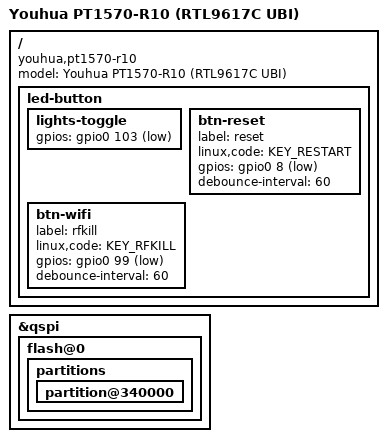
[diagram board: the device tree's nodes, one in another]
// SPDX-License-Identifier: GPL-2.0-only
//
// UNVERIFIED — DO NOT FLASH. 已按真机 FDT 完成静态移植，但尚未在新固件上启动验证。
//
// FDT_VERIFIED (2026-11-09)：以下字段来自 PT1570-R10 真机 /proc/device-tree
// 只读导出（pt1570-ci-research/r10-fdt-dump-20261109.txt，447 个属性），
// 并与 dreamtekcat/PonWRT-TYFZA1@pt1570 的 port/overlay DTS 交叉核对。
//
// 统一 UBI 方案部分完全由上游 rtl9617c-tyfza1.dtsi 提供，本文件不重复：
//   chosen.rootdisk = <&ubi_rootdisk>
//   ubi-volume-fit      { volname = "fit"; }
//   ubi-volume-factory  { volname = "factory"; nvmem-layout { ... }; }
//   分区 ubi_device <0x340000 0xf5c0000> —— 与真机 FDT 实测一致。
//
// ---- 已实证一致（由 include 的上游 4GE 定义提供，无需覆盖） ----
//   * 4×GE：realtek,lan-phys 是 4 个 phandle，指向 mdio 的 phy@1..phy@4
//     （reg 1/2/3/4，内部 GPHY）；真机 dmesg 也报 PHY 001ccac4、lan1..lan4。
//   * 12 个 LED 的 GPIO 与极性逐项一致（L=低有效 / H=高有效）：
//       internet 2L, los 10L, usb0 7H, pon 9L, power 11H, phone 12H,
//       lan0 4L, lan1 3L, lan2 1L, lan3 0L, usb1 6L, wps 5H
//   * flash 分区表 5 个分区与真机 /proc/mtd 一致。
//   * chosen / stdout-path、PON、PCIe0/PCIe1、USB、BOSA 节点由 dtsi 提供。
//
// ---- 已实证不一致、本文件覆盖 ----
//   * 按键：上游 dtsi 只有 lights-toggle(gpio 67)；真机有三键，见下方节点。
//
// ⛔ 不得改用 2.5G 板定义：它会引入一颗外置 2.5G PHY、把网口映射改成
//    NI 端口 0/1/2/4，并换成另一套 LED GPIO。R10 是 4×GE，误用会直接
//    导致 LAN 不通。这是 2026-11-09 真机核对后修正的实质缺陷。
//
// ---- 仍待验证（因此保留 UNVERIFIED） ----
//   1. 本 DTS 编译出的固件尚未在 R10 上启动过；
//   2. U-Boot Web Failsafe 网口在 R10（4×GE）上未实测；
//   3. PON / PCIe0(10ec:c852) / PCIe1(10ec:0192) / LED / 按键需开机后复测；
//   4. bootargs / rootdisk 完全沿用上游 dtsi，不在本文件覆盖。Run14 实测
//      该形态可刷入启动（当时仅 IPv4 网络层不通，已由 95-pt1570-wan-default
//      修复）；run15 起误加 /chosen 覆盖块反而把刷入态启动搞坏，见下方注释。
//
// 完成上述真机启动验证、删除 UNVERIFIED 标记后，才允许以
// dts_status=verified 编译并发布 Release。
//
// 注意：不要在此文件写 /dts-v1/；被 include 的 .dts 已经带了该标记。

#include "rtl9617c-tyfza1-4ge.dts"

/ {
	model = "Youhua PT1570-R10 (RTL9617C UBI)";
	compatible = "youhua,pt1570-r10", "tianyi,tyfza1-4ge", "realtek,rtl9617c";

	/*
	 * ⛔ 不要在这里写 /chosen 覆盖块 —— 这是 run15~run22 刷入态起不来的根因。
	 *
	 * 实证差分（2026-11-13，逐个解包 fw12~fw22 的内嵌 DTB）：
	 *   fw12 / fw14（Run14 真机刷入能启动）：
	 *     bootargs = "earlycon console=ttyS0,115200n8 loglevel=7
	 *                 clk_ignore_unused maxcpus=4"     ← 没有 root=
	 *     rootdisk = <&ubi_rootdisk>  (volname="fit")
	 *     没有 u-boot,version
	 *   fw15 / 17 / 19 / 21 / 22（全部刷入态灯全灭、无 DHCP）：
	 *     bootargs 多了 "root=/dev/fitblk0 rootwait rootfstype=squashfs"
	 *     多了 u-boot,version = "2025.01"
	 *   FIT 结构（external-data、loadables=rootfs-1、rootdisk phandle）两边完全一致。
	 *
	 * 为什么不该在这里加参数（源码依据）：
	 *   1. 这套统一 UBI 方案的挂根由内核侧完成，不依赖 bootargs 的 root=：
	 *      CONFIG_MTD_ROOTFS_ROOT_DEV 会为 chosen.rootdisk 指向的卷建
	 *      ubiblock；generic/pending-6.18/510-* 的 fitblk 驱动在
	 *      device_add_disk() 之后自己做
	 *        `if (!ROOT_DEV) ROOT_DEV = disk->part0->bd_dev;`
	 *      把 FIT 里 type=filesystem 的 rootfs 子镜像设成根设备（节点名是
	 *      FIT_DEVICE_PREFIX "fit" + slot，即 /dev/fit0）。
	 *      511-init-bypass-device-lookup-for-dev-fit-rootfs.patch 让
	 *      parse_root_device() 对 "fit*" 返回 Root_Generic 并允许 rootwait。
	 *      显式写 `root=/dev/fitblk0 rootwait` 改变了内核的挂根/等待路径，
	 *      而这个名字与驱动实际建出的 /dev/fit0 并不一致 —— 在 env 干净、
	 *      没有别的变量时，它是 run15 起的唯一新增变量。
	 *   2. fdt_support.c 的 fdt_chosen() 无条件写入 u-boot,version（在
	 *      `if (str)` 之外），所以 fitblk_init() 的门闩本来就被 U-Boot 满足；
	 *      DTS 里那份 "2025.01" 从头到尾是多余的，且会被真实版本号覆盖。
	 *      Run14 的 DTB 没有这个属性照样启动，即为实证。
	 *   3. `ubi.mtd=4` / `ubi.block=0,fit` 同样不属于这套布局：上游 dtsi 的
	 *      partition@340000 已带 `compatible = "linux,ubi"` 与 volumes
	 *      子节点，内核自动 attach；手工再指定反而可能重复 attach。
	 *
	 * 另：用户已在 U-Boot 里做过 env 清空、恢复编译默认（pt1570.env 无 bootargs），
	 * fdt_chosen() 里 `board_fdt_chosen_bootargs()` 默认返回 env_get("bootargs")
	 * = NULL，`if (str)` 不成立，根本不会覆盖 DTB。所以「NAND env 残留污染」
	 * 不是本次根因，也不需要在 U-Boot 侧加 hook（已回退）。
	 *
	 * 结论：bootargs / rootdisk / stdout-path 全部交给上游 rtl9617c-tyfza1.dtsi，
	 * 本文件不覆盖，精确复现 Run14 已验证可启动的形态。
	 */

	/*
	 * ubi_device 分区的 read-only 在本文件末尾的 &qspi 覆盖块里删除，
	 * 原因见那里的注释（UBI 只读会直接导致刷入态启动失败）。
	 */

	// 覆盖上游 dtsi 的 led-button：修正 lights 引脚，补齐 reset / wifi。
	// DTC 会合并同名节点，同名子节点按后写覆盖。
	// 真机 FDT 实测（gpios 三元组 phandle / pin / flags）：
	//   lights_toggle  pin=103 flags=1  linux,code=0x21e
	//   reset          pin=8   flags=1  linux,code=0x198
	//   rfkill         pin=99  flags=1  linux,code=0xf7
	led-button {
		lights-toggle {
			gpios = <&gpio0 103 GPIO_ACTIVE_LOW>;
		};

		btn-reset {
			label = "reset";
			linux,code = <KEY_RESTART>;
			gpios = <&gpio0 8 GPIO_ACTIVE_LOW>;
			debounce-interval = <60>;
		};

		btn-wifi {
			label = "rfkill";
			linux,code = <KEY_RFKILL>;
			gpios = <&gpio0 99 GPIO_ACTIVE_LOW>;
			debounce-interval = <60>;
		};
	};
};

/*
 * ubi_device 分区必须可写（2026-11-12 真机定位）
 *
 * 上游 rtl9617c-tyfza1.dtsi 给 5 个分区都写了 read-only，并用
 * 110-spinand-readonly.patch 在 spinand_probe 里把带 read-only 的 MTD
 * 的 MTD_WRITEABLE 清掉。于是内核把 mtd4 判成写保护，UBI 以只读方式 attach：
 *   ubi0: MTD device 4 is write-protected, attach in read-only mode
 *   ubimkvol -> error 30 (Read-only file system)
 * 结果 rootfs_data（刷机后整卷 0xFF）永远无法格式化成 ubifs，mount_root
 * 建不出 overlay，刷入态启动必然失败。这里只放开 ubi_device；
 * boot / env / env2 / static_conf 保持只读。
 */
&qspi {
	flash@0 {
		partitions {
			partition@340000 {
				/delete-property/ read-only;
			};
		};
	};
};
